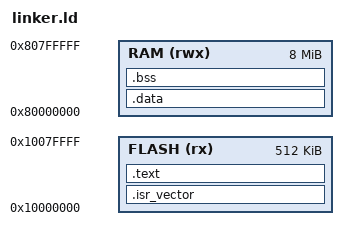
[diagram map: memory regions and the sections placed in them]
ENTRY(Reset_Handler)

MEMORY
{
    FLASH (rx)  : ORIGIN = 0x10000000, LENGTH = 512K
    RAM   (rwx) : ORIGIN = 0x80000000, LENGTH = 8M
}

PHDRS
{
    text PT_LOAD FLAGS(5);
    data PT_LOAD FLAGS(6);
}

_estack = ORIGIN(RAM) + LENGTH(RAM);

SECTIONS
{
    .isr_vector :
    {
        KEEP(*(.isr_vector))
    } > FLASH :text

    .text :
    {
        *(.text*)
        *(.rodata*)
        . = ALIGN(4);
        _etext = .;
    } > FLASH :text

    .data : AT(_etext)
    {
        . = ALIGN(4);
        _sdata = .;
        *(.data*)
        . = ALIGN(4);
        _edata = .;
    } > RAM :data

    _sidata = LOADADDR(.data);

    .bss (NOLOAD) :
    {
        . = ALIGN(4);
        _sbss = .;
        *(.bss*)
        *(COMMON)
        . = ALIGN(4);
        _ebss = .;
    } > RAM :NONE
}
